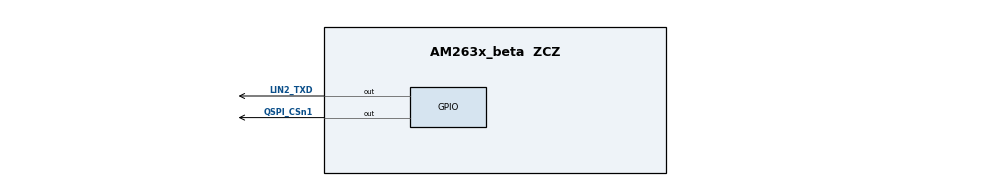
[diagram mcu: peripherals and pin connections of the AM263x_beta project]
/**
 * @cliArgs --device "AM263x_beta" --package "ZCZ" --part "AM263x" --context "r5fss0-0" --product "INDUSTRIAL_COMMUNICATIONS_SDK_AM263X@09.01.00"
 * @versions {"tool":"1.19.0+3426"}
 */

/**
 * Import the modules used in this configuration.
 */
const eeprom          = scripting.addModule("/board/eeprom/eeprom", {}, false);
const eeprom1         = eeprom.addInstance();
const flash           = scripting.addModule("/board/flash/flash", {}, false);
const flash1          = flash.addInstance();
const led             = scripting.addModule("/board/led/led", {}, false);
const led1            = led.addInstance();
const led2            = led.addInstance();
const led3            = led.addInstance();
const gpio            = scripting.addModule("/drivers/gpio/gpio", {}, false);
const gpio1           = gpio.addInstance();
const gpio2           = gpio.addInstance();
const i2c             = scripting.addModule("/drivers/i2c/i2c", {}, false);
const i2c1            = i2c.addInstance();
const i2c2            = i2c.addInstance();
const ethercat        = scripting.addModule("/industrial_comms/ethercat/ethercat", {}, false);
const ethercat1       = ethercat.addInstance();
const debug_log       = scripting.addModule("/kernel/dpl/debug_log");
const mpu_armv7       = scripting.addModule("/kernel/dpl/mpu_armv7", {}, false);
const mpu_armv71      = mpu_armv7.addInstance();
const mpu_armv72      = mpu_armv7.addInstance();
const mpu_armv73      = mpu_armv7.addInstance();
const mpu_armv74      = mpu_armv7.addInstance();
const mpu_armv75      = mpu_armv7.addInstance();
const mpu_armv76      = mpu_armv7.addInstance();
const default_linker  = scripting.addModule("/memory_configurator/default_linker", {}, false);
const default_linker1 = default_linker.addInstance();
const general         = scripting.addModule("/memory_configurator/general", {}, false);
const general1        = general.addInstance();
const region          = scripting.addModule("/memory_configurator/region", {}, false);
const region1         = region.addInstance();
const section         = scripting.addModule("/memory_configurator/section", {}, false);
const section1        = section.addInstance();
const section2        = section.addInstance();
const section3        = section.addInstance();
const section4        = section.addInstance();
const section5        = section.addInstance();
const section6        = section.addInstance();
const section7        = section.addInstance();
const section8        = section.addInstance();
const section9        = section.addInstance();
const section10       = section.addInstance();
const section11       = section.addInstance();
const section12       = section.addInstance();

/**
 * Write custom configuration values to the imported modules.
 */
eeprom1.$name = "CONFIG_EEPROM0";

flash1.$name                  = "CONFIG_FLASH0";
flash1.peripheralDriver.$name = "CONFIG_QSPI0";

led1.name  = "TPIC2810";
led1.$name = "CONFIG_LED_DIGITAL_OUTPUT";

led2.$name = "CONFIG_LED_RUN";

led3.$name = "CONFIG_LED_ERROR";

const edma                         = scripting.addModule("/drivers/edma/edma", {}, false);
const edma1                        = edma.addInstance({}, false);
edma1.$name                        = "CONFIG_EDMA0";
flash1.peripheralDriver.edmaConfig = edma1;
edma1.edmaRmDmaCh[0].$name         = "CONFIG_EDMA_RM0";
edma1.edmaRmQdmaCh[0].$name        = "CONFIG_EDMA_RM1";
edma1.edmaRmTcc[0].$name           = "CONFIG_EDMA_RM2";
edma1.edmaRmParam[0].$name         = "CONFIG_EDMA_RM3";

gpio1.$name                = "CONFIG_GPIO0";
led2.peripheralDriver      = gpio1;
gpio1.pinDir               = "OUTPUT";
gpio1.GPIO.gpioPin.$assign = "QSPI_CSn1";

gpio2.$name                = "CONFIG_GPIO1";
led3.peripheralDriver      = gpio2;
gpio2.pinDir               = "OUTPUT";
gpio2.GPIO.gpioPin.$assign = "LIN2_TXD";

led1.peripheralDriver = i2c1;
i2c1.$name            = "CONFIG_I2C2";
i2c1.I2C.$assign      = "I2C2";
i2c1.I2C.SCL.$assign  = "UART0_RTSn";
i2c1.I2C.SDA.$assign  = "UART0_CTSn";

i2c2.$name               = "CONFIG_I2C0";
eeprom1.peripheralDriver = i2c2;
i2c2.I2C.$assign         = "I2C0";
i2c2.I2C.SCL.$assign     = "I2C0_SCL";
i2c2.I2C.SDA.$assign     = "I2C0_SDA";

ethercat1.$name              = "CONFIG_ETHERCAT0";
ethercat1.ethphy[0].$name    = "CONFIG_ETHPHY0";
ethercat1.ethphy[0].mdioPort = 3;
ethercat1.ethphy[1].$name    = "CONFIG_ETHPHY1";
ethercat1.ethphy[1].name     = "DP83826E";
ethercat1.ethphy[1].mdioPort = 1;

const pruicss                            = scripting.addModule("/drivers/pruicss/pruicss", {}, false);
const pruicss1                           = pruicss.addInstance({}, false);
pruicss1.$name                           = "CONFIG_PRU_ICSS0";
ethercat1.icss                           = pruicss1;
pruicss1.AdditionalICSSSettings[0].$name = "CONFIG_PRU_ICSS_IO1";

debug_log.enableUartLog            = true;
debug_log.enableCssLog             = false;
debug_log.uartLog.$name            = "CONFIG_UART0";
debug_log.uartLog.UART.$assign     = "UART0";
debug_log.uartLog.UART.RXD.$assign = "UART0_RXD";
debug_log.uartLog.UART.TXD.$assign = "UART0_TXD";
debug_log.uartLog.child.$name      = "drivers_uart_v2_uart_v2_template0";

mpu_armv71.$name             = "CONFIG_MPU_REGION0";
mpu_armv71.size              = 31;
mpu_armv71.attributes        = "Device";
mpu_armv71.accessPermissions = "Supervisor RD+WR, User RD";
mpu_armv71.allowExecute      = false;

mpu_armv72.$name             = "CONFIG_MPU_REGION1";
mpu_armv72.size              = 15;
mpu_armv72.accessPermissions = "Supervisor RD+WR, User RD";

mpu_armv73.$name             = "CONFIG_MPU_REGION2";
mpu_armv73.baseAddr          = 0x80000;
mpu_armv73.size              = 15;
mpu_armv73.accessPermissions = "Supervisor RD+WR, User RD";

mpu_armv74.$name             = "CONFIG_MPU_REGION3";
mpu_armv74.accessPermissions = "Supervisor RD+WR, User RD";
mpu_armv74.baseAddr          = 0x70000000;
mpu_armv74.size              = 21;

mpu_armv75.$name        = "CONFIG_MPU_REGION4";
mpu_armv75.size         = 14;
mpu_armv75.baseAddr     = 0x50D00000;
mpu_armv75.allowExecute = false;
mpu_armv75.attributes   = "Device";

mpu_armv76.$name        = "CONFIG_MPU_REGION5";
mpu_armv76.size         = 14;
mpu_armv76.allowExecute = false;
mpu_armv76.attributes   = "NonCached";
mpu_armv76.baseAddr     = 0x72000000;

default_linker1.$name = "memory_configurator_default_linker0";

general1.$name        = "CONFIG_GENERAL0";
general1.stack_size   = 32768;
general1.linker.$name = "TIARMCLANG0";

region1.$name                               = "MEMORY_REGION_CONFIGURATION0";
region1.memory_region.create(10);
region1.memory_region[0].type               = "TCMA";
region1.memory_region[0].$name              = "R5F_VECS";
region1.memory_region[0].size               = 0x40;
region1.memory_region[0].auto               = false;
region1.memory_region[1].type               = "TCMA";
region1.memory_region[1].$name              = "R5F_TCMA";
region1.memory_region[1].size               = 0x7FC0;
region1.memory_region[2].type               = "TCMB";
region1.memory_region[2].size               = 0x8000;
region1.memory_region[2].$name              = "R5F_TCMB";
region1.memory_region[3].$name              = "OCRAM";
region1.memory_region[3].auto               = false;
region1.memory_region[3].manualStartAddress = 0x70080000;
region1.memory_region[3].size               = 0x80000;
region1.memory_region[4].type               = "FLASH";
region1.memory_region[4].auto               = false;
region1.memory_region[4].size               = 0x80000;
region1.memory_region[4].$name              = "FLASH";
region1.memory_region[5].$name              = "USER_SHM_MEM";
region1.memory_region[5].auto               = false;
region1.memory_region[5].manualStartAddress = 0x701D0000;
region1.memory_region[5].size               = 0x4000;
region1.memory_region[5].isShared           = true;
region1.memory_region[5].shared_cores       = ["r5fss0-1","r5fss1-0","r5fss1-1"];
region1.memory_region[6].$name              = "LOG_SHM_MEM";
region1.memory_region[6].auto               = false;
region1.memory_region[6].manualStartAddress = 0x701D4000;
region1.memory_region[6].size               = 0x4000;
region1.memory_region[6].isShared           = true;
region1.memory_region[6].shared_cores       = ["r5fss0-1","r5fss1-0","r5fss1-1"];
region1.memory_region[7].type               = "CUSTOM";
region1.memory_region[7].$name              = "RTOS_NORTOS_IPC_SHM_MEM";
region1.memory_region[7].auto               = false;
region1.memory_region[7].manualStartAddress = 0x72000000;
region1.memory_region[7].size               = 0x3E80;
region1.memory_region[7].isShared           = true;
region1.memory_region[7].shared_cores       = ["r5fss0-1","r5fss1-0","r5fss1-1"];
region1.memory_region[8].type               = "CUSTOM";
region1.memory_region[8].$name              = "MAILBOX_HSM";
region1.memory_region[8].auto               = false;
region1.memory_region[8].manualStartAddress = 0x44000000;
region1.memory_region[8].size               = 0x3CE;
region1.memory_region[8].isShared           = true;
region1.memory_region[8].shared_cores       = ["r5fss0-1","r5fss1-0","r5fss1-1"];
region1.memory_region[9].type               = "CUSTOM";
region1.memory_region[9].$name              = "MAILBOX_R5F";
region1.memory_region[9].auto               = false;
region1.memory_region[9].manualStartAddress = 0x44000400;
region1.memory_region[9].size               = 0x3CE;
region1.memory_region[9].isShared           = true;
region1.memory_region[9].shared_cores       = ["r5fss0-1","r5fss1-0","r5fss1-1"];

section1.load_memory                  = "R5F_VECS";
section1.group                        = false;
section1.$name                        = "Vector Table";
section1.output_section.create(1);
section1.output_section[0].$name      = ".vectors";
section1.output_section[0].palignment = true;

section2.load_memory                  = "OCRAM";
section2.$name                        = "Text Segments";
section2.output_section.create(5);
section2.output_section[0].$name      = ".text.hwi";
section2.output_section[0].palignment = true;
section2.output_section[1].$name      = ".text.cache";
section2.output_section[1].palignment = true;
section2.output_section[2].$name      = ".text.mpu";
section2.output_section[2].palignment = true;
section2.output_section[3].$name      = ".text.boot";
section2.output_section[3].palignment = true;
section2.output_section[4].$name      = ".text:abort";
section2.output_section[4].palignment = true;

section3.load_memory                  = "OCRAM";
section3.$name                        = "Code and Read-Only Data";
section3.output_section.create(2);
section3.output_section[0].$name      = ".text";
section3.output_section[0].palignment = true;
section3.output_section[1].$name      = ".rodata";
section3.output_section[1].palignment = true;

section4.load_memory                  = "OCRAM";
section4.$name                        = "Data Segment";
section4.output_section.create(1);
section4.output_section[0].$name      = ".data";
section4.output_section[0].palignment = true;

section5.load_memory                             = "OCRAM";
section5.$name                                   = "Memory Segments";
section5.output_section.create(3);
section5.output_section[0].$name                 = ".bss";
section5.output_section[0].output_sections_start = "__BSS_START";
section5.output_section[0].output_sections_end   = "__BSS_END";
section5.output_section[0].palignment            = true;
section5.output_section[1].$name                 = ".sysmem";
section5.output_section[1].palignment            = true;
section5.output_section[2].$name                 = ".stack";
section5.output_section[2].palignment            = true;

section6.load_memory                              = "OCRAM";
section6.$name                                    = "Stack Segments";
section6.output_section.create(5);
section6.output_section[0].$name                  = ".irqstack";
section6.output_section[0].output_sections_start  = "__IRQ_STACK_START";
section6.output_section[0].output_sections_end    = "__IRQ_STACK_END";
section6.output_section[0].input_section.create(1);
section6.output_section[0].input_section[0].$name = ". = . + __IRQ_STACK_SIZE;";
section6.output_section[1].$name                  = ".fiqstack";
section6.output_section[1].output_sections_start  = "__FIQ_STACK_START";
section6.output_section[1].output_sections_end    = "__FIQ_STACK_END";
section6.output_section[1].input_section.create(1);
section6.output_section[1].input_section[0].$name = ". = . + __FIQ_STACK_SIZE;";
section6.output_section[2].$name                  = ".svcstack";
section6.output_section[2].output_sections_start  = "__SVC_STACK_START";
section6.output_section[2].output_sections_end    = "__SVC_STACK_END";
section6.output_section[2].input_section.create(1);
section6.output_section[2].input_section[0].$name = ". = . + __SVC_STACK_SIZE;";
section6.output_section[3].$name                  = ".abortstack";
section6.output_section[3].output_sections_start  = "__ABORT_STACK_START";
section6.output_section[3].output_sections_end    = "__ABORT_STACK_END";
section6.output_section[3].input_section.create(1);
section6.output_section[3].input_section[0].$name = ". = . + __ABORT_STACK_SIZE;";
section6.output_section[4].$name                  = ".undefinedstack";
section6.output_section[4].output_sections_start  = "__UNDEFINED_STACK_START";
section6.output_section[4].output_sections_end    = "__UNDEFINED_STACK_END";
section6.output_section[4].input_section.create(1);
section6.output_section[4].input_section[0].$name = ". = . + __UNDEFINED_STACK_SIZE;";

section7.load_memory                  = "OCRAM";
section7.$name                        = "Initialization and Exception Handling";
section7.output_section.create(3);
section7.output_section[0].$name      = ".ARM.exidx";
section7.output_section[0].palignment = true;
section7.output_section[1].$name      = ".init_array";
section7.output_section[1].palignment = true;
section7.output_section[2].$name      = ".fini_array";
section7.output_section[2].palignment = true;

section8.load_memory                 = "USER_SHM_MEM";
section8.type                        = "NOLOAD";
section8.$name                       = "User Shared Memory";
section8.group                       = false;
section8.output_section.create(1);
section8.output_section[0].$name     = ".bss.user_shared_mem";
section8.output_section[0].alignment = 0;

section9.load_memory                 = "LOG_SHM_MEM";
section9.$name                       = "Log Shared Memory";
section9.group                       = false;
section9.type                        = "NOLOAD";
section9.output_section.create(1);
section9.output_section[0].$name     = ".bss.log_shared_mem";
section9.output_section[0].alignment = 0;

section10.load_memory                 = "RTOS_NORTOS_IPC_SHM_MEM";
section10.type                        = "NOLOAD";
section10.$name                       = "IPC Shared Memory";
section10.group                       = false;
section10.output_section.create(1);
section10.output_section[0].$name     = ".bss.ipc_vring_mem";
section10.output_section[0].alignment = 0;

section11.load_memory                 = "MAILBOX_HSM";
section11.type                        = "NOLOAD";
section11.$name                       = "SIPC HSM Queue Memory";
section11.group                       = false;
section11.output_section.create(1);
section11.output_section[0].$name     = ".bss.sipc_hsm_queue_mem";
section11.output_section[0].alignment = 0;

section12.load_memory                 = "MAILBOX_R5F";
section12.$name                       = "SIPC R5F Queue Memory";
section12.group                       = false;
section12.type                        = "NOLOAD";
section12.output_section.create(1);
section12.output_section[0].$name     = ".bss.sipc_r5f_queue_mem";
section12.output_section[0].alignment = 0;

/**
 * Pinmux solution for unlocked pins/peripherals. This ensures that minor changes to the automatic solver in a future
 * version of the tool will not impact the pinmux you originally saw.  These lines can be completely deleted in order to
 * re-solve from scratch.
 */
flash1.peripheralDriver.QSPI.$suggestSolution                    = "QSPI";
flash1.peripheralDriver.QSPI.QSPI_D0.$suggestSolution            = "QSPI_D0";
flash1.peripheralDriver.QSPI.QSPI_D1.$suggestSolution            = "QSPI_D1";
flash1.peripheralDriver.QSPI.QSPI_D2.$suggestSolution            = "QSPI_D2";
flash1.peripheralDriver.QSPI.QSPI_D3.$suggestSolution            = "QSPI_D3";
flash1.peripheralDriver.QSPI.QSPI_CLK.$suggestSolution           = "QSPI_CLK";
flash1.peripheralDriver.QSPI.QSPI_CSn0.$suggestSolution          = "QSPI_CSn0";
gpio1.GPIO.$suggestSolution                                      = "GPIO0";
gpio2.GPIO.$suggestSolution                                      = "GPIO0";
ethercat1.ICSSM_IEP.$suggestSolution                             = "ICSSM_IEP";
ethercat1.ICSSM_IEP.PR0_IEP0_EDC_SYNC_OUT0.$suggestSolution      = "PR0_PRU1_GPIO19";
ethercat1.ICSSM_IEP.PR0_IEP0_EDC_SYNC_OUT1.$suggestSolution      = "SDFM0_CLK1";
ethercat1.ICSSM_IEP.PR0_IEP0_EDIO_DATA_IN_OUT30.$suggestSolution = "SDFM0_D1";
ethercat1.ICSSM_IEP.PR0_IEP0_EDIO_DATA_IN_OUT31.$suggestSolution = "PR0_PRU1_GPIO18";
ethercat1.ICSSM.$suggestSolution                                 = "ICSSM";
ethercat1.ICSSM.PR0_MDIO_MDIO.$suggestSolution                   = "PR0_MDIO_MDIO";
ethercat1.ICSSM.PR0_MDIO_MDC.$suggestSolution                    = "PR0_MDIO_MDC";
ethercat1.ICSSM.PR0_PRU0_GPIO0.$suggestSolution                  = "PR0_PRU0_GPIO0";
ethercat1.ICSSM.PR0_PRU0_GPIO1.$suggestSolution                  = "PR0_PRU0_GPIO1";
ethercat1.ICSSM.PR0_PRU0_GPIO2.$suggestSolution                  = "PR0_PRU0_GPIO2";
ethercat1.ICSSM.PR0_PRU0_GPIO3.$suggestSolution                  = "PR0_PRU0_GPIO3";
ethercat1.ICSSM.PR0_PRU0_GPIO4.$suggestSolution                  = "PR0_PRU0_GPIO4";
ethercat1.ICSSM.PR0_PRU0_GPIO5.$suggestSolution                  = "PR0_PRU0_GPIO5";
ethercat1.ICSSM.PR0_PRU0_GPIO6.$suggestSolution                  = "PR0_PRU0_GPIO6";
ethercat1.ICSSM.PR0_PRU0_GPIO8.$suggestSolution                  = "PR0_PRU0_GPIO8";
ethercat1.ICSSM.PR0_PRU0_GPIO9.$suggestSolution                  = "PR0_PRU0_GPIO9";
ethercat1.ICSSM.PR0_PRU0_GPIO10.$suggestSolution                 = "PR0_PRU0_GPIO10";
ethercat1.ICSSM.PR0_PRU0_GPIO11.$suggestSolution                 = "PR0_PRU0_GPIO11";
ethercat1.ICSSM.PR0_PRU0_GPIO12.$suggestSolution                 = "PR0_PRU0_GPIO12";
ethercat1.ICSSM.PR0_PRU0_GPIO13.$suggestSolution                 = "PR0_PRU0_GPIO13";
ethercat1.ICSSM.PR0_PRU0_GPIO14.$suggestSolution                 = "PR0_PRU0_GPIO14";
ethercat1.ICSSM.PR0_PRU0_GPIO15.$suggestSolution                 = "PR0_PRU0_GPIO15";
ethercat1.ICSSM.PR0_PRU0_GPIO16.$suggestSolution                 = "PR0_PRU0_GPIO16";
ethercat1.ICSSM.PR0_PRU1_GPIO0.$suggestSolution                  = "PR0_PRU1_GPIO0";
ethercat1.ICSSM.PR0_PRU1_GPIO1.$suggestSolution                  = "PR0_PRU1_GPIO1";
ethercat1.ICSSM.PR0_PRU1_GPIO2.$suggestSolution                  = "PR0_PRU1_GPIO2";
ethercat1.ICSSM.PR0_PRU1_GPIO3.$suggestSolution                  = "PR0_PRU1_GPIO3";
ethercat1.ICSSM.PR0_PRU1_GPIO4.$suggestSolution                  = "PR0_PRU1_GPIO4";
ethercat1.ICSSM.PR0_PRU1_GPIO5.$suggestSolution                  = "PR0_PRU1_GPIO5";
ethercat1.ICSSM.PR0_PRU1_GPIO6.$suggestSolution                  = "PR0_PRU1_GPIO6";
ethercat1.ICSSM.PR0_PRU1_GPIO8.$suggestSolution                  = "PR0_PRU1_GPIO8";
ethercat1.ICSSM.PR0_PRU1_GPIO9.$suggestSolution                  = "PR0_PRU1_GPIO9";
ethercat1.ICSSM.PR0_PRU1_GPIO10.$suggestSolution                 = "PR0_PRU1_GPIO10";
ethercat1.ICSSM.PR0_PRU1_GPIO11.$suggestSolution                 = "PR0_PRU1_GPIO11";
ethercat1.ICSSM.PR0_PRU1_GPIO12.$suggestSolution                 = "PR0_PRU1_GPIO12";
ethercat1.ICSSM.PR0_PRU1_GPIO13.$suggestSolution                 = "PR0_PRU1_GPIO13";
ethercat1.ICSSM.PR0_PRU1_GPIO14.$suggestSolution                 = "PR0_PRU1_GPIO14";
ethercat1.ICSSM.PR0_PRU1_GPIO15.$suggestSolution                 = "PR0_PRU1_GPIO15";
ethercat1.ICSSM.PR0_PRU1_GPIO16.$suggestSolution                 = "PR0_PRU1_GPIO16";
